# CY8C4245AXI_483 register map
File version: 0.1
PSoC 4200
Registers are 32-bit, read-write, no defined reset value unless marked. A register's access mark holds for its fields unless they carry their own. Offsets are from the block's base; lines under a group give offsets from that group; [hi:lo] are bit positions; {n}, {i} and the like mark numbered series; 'fields as' and 'values as' point back to an identical list; <NAME> marks a mode.

## Memory map
0x00000000 TelemUART — UART
0x00000000 ServoTimer
0x00000000 I2CM — Serial Communication Block
0x00000000 ADC — Sequencing SAR ADC
0x00000000 NavLightPWM
0x00000000 TaskTimer
0x00000000 UART_1 — Serial Communication Block
0x00000000 PPMCounter

## TelemUART — UART
Base 0x00000000
0x400F0043 TX_TelemUART_TX_DATA 8-bit — TX Data Register
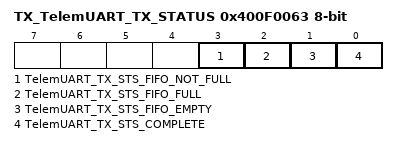
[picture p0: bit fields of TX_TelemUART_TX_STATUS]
0x400F0063 TX_TelemUART_TX_STATUS 8-bit — TX status register
  [3] TelemUART_TX_STS_FIFO_NOT_FULL ro, [2] TelemUART_TX_STS_FIFO_FULL ro, [1] TelemUART_TX_STS_FIFO_EMPTY ro, [0] TelemUART_TX_STS_COMPLETE ro

## ServoTimer
Base 0x00000000
0x40050148 COUNTER — Current counter value
0x4005014C CC — Compare / capture value
0x40050150 CC_BUF — Compare / capture buffer value
0x40050154 PERIOD — Period value
0x40050158 PERIOD_BUF — Period buffer value

## NavLightPWM
Base 0x00000000
0x40050188 COUNTER — Current counter value
0x4005018C CC — Compare / capture value
0x40050190 CC_BUF — Compare / capture buffer value
0x40050194 PERIOD — Period value
0x40050198 PERIOD_BUF — Period buffer value

## TaskTimer
Base 0x00000000
0x40050108 COUNTER — Current counter value
0x4005010C CC — Compare / capture value
0x40050110 CC_BUF — Compare / capture buffer value
0x40050114 PERIOD — Period value
0x40050118 PERIOD_BUF — Period buffer value

## PPMCounter
Base 0x00000000
0x400501C8 COUNTER — Current counter value
0x400501CC CC — Compare / capture value
0x400501D0 CC_BUF — Compare / capture buffer value
0x400501D4 PERIOD — Period value
0x400501D8 PERIOD_BUF — Period buffer value
